# STM32F730x register map
File version: 1.1
CPU: CM7 r0p1, little endian, MPU, FPU, 4 interrupt priority bits
Registers are 32-bit, read-write, reset 0x0 unless marked. A register's access mark holds for its fields unless they carry their own. Offsets are from the block's base; [hi:lo] are bit positions; {n}, {i} and the like mark numbered series; 'fields as' and 'values as' point back to an identical list.

## FMC — Flexible memory controller
Base 0xA0000000
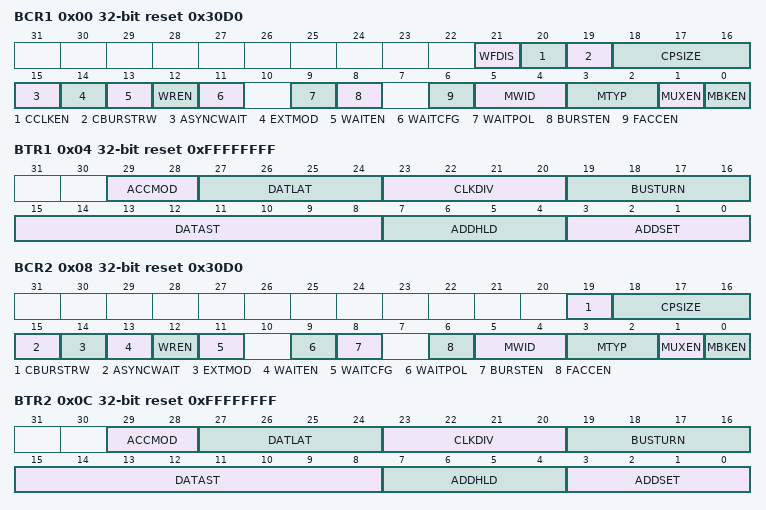
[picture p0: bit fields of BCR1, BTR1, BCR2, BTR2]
0x00 BCR1 reset 0x30D0 — SRAM/NOR-Flash chip-select control register 1
  [21] WFDIS — Write FIFO Disable
  [20] CCLKEN
  [19] CBURSTRW
  [18:16] CPSIZE — CRAM page size
  [15] ASYNCWAIT
  [14] EXTMOD
  [13] WAITEN
  [12] WREN
  [11] WAITCFG
  [9] WAITPOL
  [8] BURSTEN
  [6] FACCEN
  [5:4] MWID
  [3:2] MTYP
  [1] MUXEN
  [0] MBKEN
0x04 BTR1 reset 0xFFFFFFFF — SRAM/NOR-Flash chip-select timing register 1
  [29:28] ACCMOD, [27:24] DATLAT, [23:20] CLKDIV, [19:16] BUSTURN, [15:8] DATAST, [7:4] ADDHLD, [3:0] ADDSET
0x08 BCR2 reset 0x30D0 — SRAM/NOR-Flash chip-select control register 2
  [19] CBURSTRW
  [18:16] CPSIZE — CRAM page size
  [15] ASYNCWAIT
  [14] EXTMOD
  [13] WAITEN
  [12] WREN
  [11] WAITCFG
  [9] WAITPOL
  [8] BURSTEN
  [6] FACCEN
  [5:4] MWID
  [3:2] MTYP
  [1] MUXEN
  [0] MBKEN
0x0C BTR2 reset 0xFFFFFFFF — SRAM/NOR-Flash chip-select timing register 2
  fields as BTR1
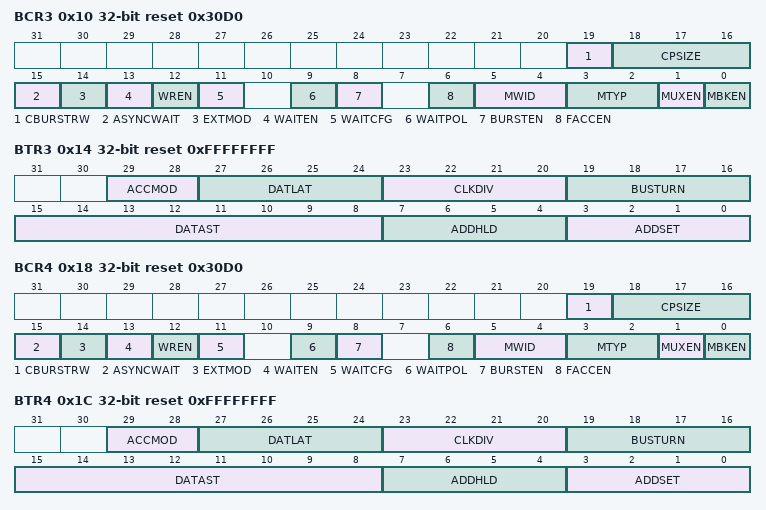
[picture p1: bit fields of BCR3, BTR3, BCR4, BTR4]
0x10 BCR3 reset 0x30D0 — SRAM/NOR-Flash chip-select control register 3
  [19] CBURSTRW
  [18:16] CPSIZE — CRAM page size.
  [15] ASYNCWAIT
  [14] EXTMOD
  [13] WAITEN
  [12] WREN
  [11] WAITCFG
  [9] WAITPOL
  [8] BURSTEN
  [6] FACCEN
  [5:4] MWID
  [3:2] MTYP
  [1] MUXEN
  [0] MBKEN
0x14 BTR3 reset 0xFFFFFFFF — SRAM/NOR-Flash chip-select timing register 3
  fields as BTR1
0x18 BCR4 reset 0x30D0 — SRAM/NOR-Flash chip-select control register 4
  fields as BCR3
0x1C BTR4 reset 0xFFFFFFFF — SRAM/NOR-Flash chip-select timing register 4
  fields as BTR1
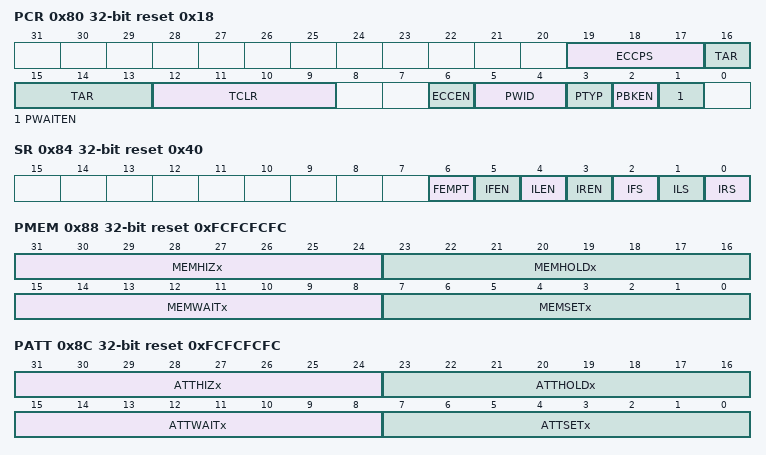
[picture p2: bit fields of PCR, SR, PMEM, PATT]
0x80 PCR reset 0x18 — PC Card/NAND Flash control register
  [19:17] ECCPS, [16:13] TAR, [12:9] TCLR, [6] ECCEN, [5:4] PWID, [3] PTYP, [2] PBKEN, [1] PWAITEN
0x84 SR access per field reset 0x40 — FIFO status and interrupt register
  [6] FEMPT ro, [5] IFEN rw, [4] ILEN rw, [3] IREN rw, [2] IFS rw, [1] ILS rw, [0] IRS rw
0x88 PMEM reset 0xFCFCFCFC — Common memory space timing register
  [31:24] MEMHIZx, [23:16] MEMHOLDx, [15:8] MEMWAITx, [7:0] MEMSETx
0x8C PATT reset 0xFCFCFCFC — Attribute memory space timing register
  [31:24] ATTHIZx, [23:16] ATTHOLDx, [15:8] ATTWAITx, [7:0] ATTSETx
0x94 ECCR ro — ECC result register
  [31:0] ECCx
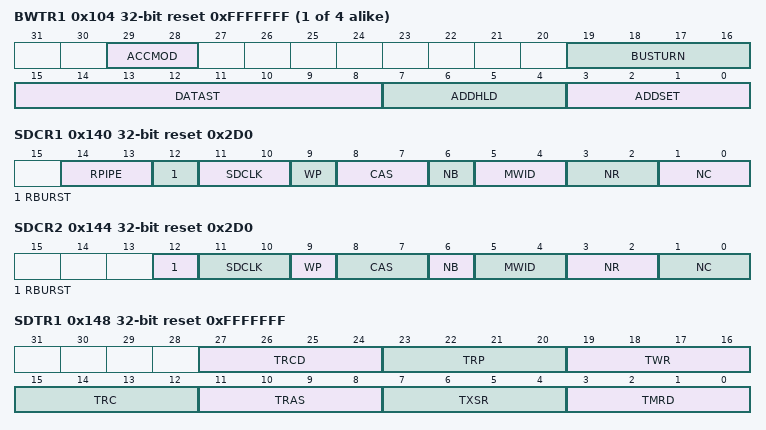
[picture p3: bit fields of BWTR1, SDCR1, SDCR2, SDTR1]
{0xFC+8i} BWTR{i} reset 0xFFFFFFF (i=1..4) — SRAM/NOR-Flash write timing registers {i}
  [29:28] ACCMOD
  [19:16] BUSTURN — Bus turnaround phase duration
  [15:8] DATAST
  [7:4] ADDHLD
  [3:0] ADDSET
0x140 SDCR1 reset 0x2D0 — SDRAM Control Register 1
  [14:13] RPIPE — Read pipe
  [12] RBURST — Burst read
  [11:10] SDCLK — SDRAM clock configuration
  [9] WP — Write protection
  [8:7] CAS — CAS latency
  [6] NB — Number of internal banks
  [5:4] MWID — Memory data bus width
  [3:2] NR — Number of row address bits
  [1:0] NC — Number of column address bits
0x144 SDCR2 reset 0x2D0 — SDRAM Control Register 2
  [12] RBURST — Burst read
  [11:10] SDCLK — SDRAM clock configuration
  [9] WP — Write protection
  [8:7] CAS — CAS latency
  [6] NB — Number of internal banks
  [5:4] MWID — Memory data bus width
  [3:2] NR — Number of row address bits
  [1:0] NC — Number of column address bits
0x148 SDTR1 reset 0xFFFFFFF — SDRAM Timing register 1
  [27:24] TRCD — Row to column delay
  [23:20] TRP — Row precharge delay
  [19:16] TWR — Recovery delay
  [15:12] TRC — Row cycle delay
  [11:8] TRAS — Self refresh time
  [7:4] TXSR — Exit self-refresh delay
  [3:0] TMRD — Load Mode Register to Active
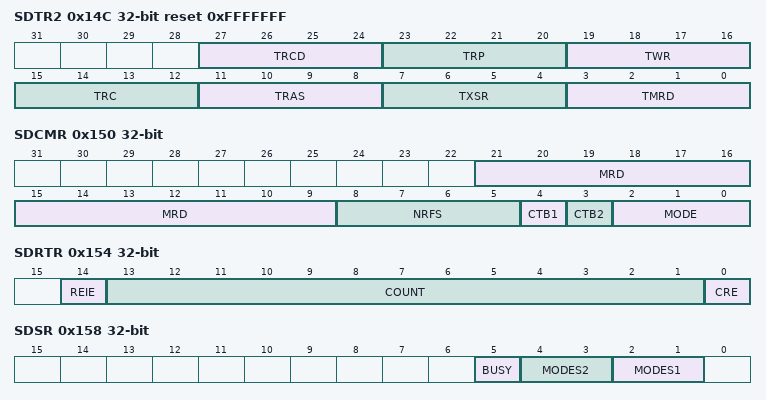
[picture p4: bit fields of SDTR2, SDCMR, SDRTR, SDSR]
0x14C SDTR2 reset 0xFFFFFFF — SDRAM Timing register 2
  fields as SDTR1
0x150 SDCMR access per field — SDRAM Command Mode register
  [21:9] MRD rw — Mode Register definition
  [8:5] NRFS rw — Number of Auto-refresh
  [4] CTB1 wo — Command target bank 1
  [3] CTB2 wo — Command target bank 2
  [2:0] MODE wo — Command mode
0x154 SDRTR access per field — SDRAM Refresh Timer register
  [14] REIE rw — RES Interrupt Enable
  [13:1] COUNT rw — Refresh Timer Count
  [0] CRE wo — Clear Refresh error flag
0x158 SDSR ro — SDRAM Status register
  [5] BUSY — Busy status
  [4:3] MODES2 — Status Mode for Bank 2
  [2:1] MODES1 — Status Mode for Bank 1
